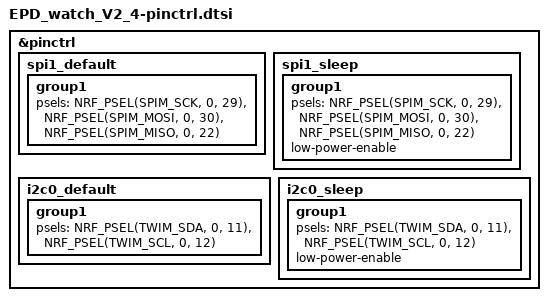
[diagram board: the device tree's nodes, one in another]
&pinctrl
{
    spi1_default: spi1_default
    {
        group1
        {
            psels = <NRF_PSEL(SPIM_SCK,  0, 29)>,
                    <NRF_PSEL(SPIM_MOSI, 0, 30)>,
                    <NRF_PSEL(SPIM_MISO, 0, 22)>;
        };
    };

    spi1_sleep: spi1_sleep
    {
        group1
        {
            psels = <NRF_PSEL(SPIM_SCK,  0, 29)>,
                    <NRF_PSEL(SPIM_MOSI, 0, 30)>,
                    <NRF_PSEL(SPIM_MISO, 0, 22)>;
            low-power-enable;
        };
    };

	i2c0_default: i2c0_default
	{
		group1
		{
			psels = <NRF_PSEL(TWIM_SDA, 0, 11)>,
					<NRF_PSEL(TWIM_SCL, 0, 12)>;
		};
	};

	i2c0_sleep: i2c0_sleep
	{
		group1
		{
			psels = <NRF_PSEL(TWIM_SDA, 0, 11)>,
					<NRF_PSEL(TWIM_SCL, 0, 12)>;
			low-power-enable;
		};
	};
};
